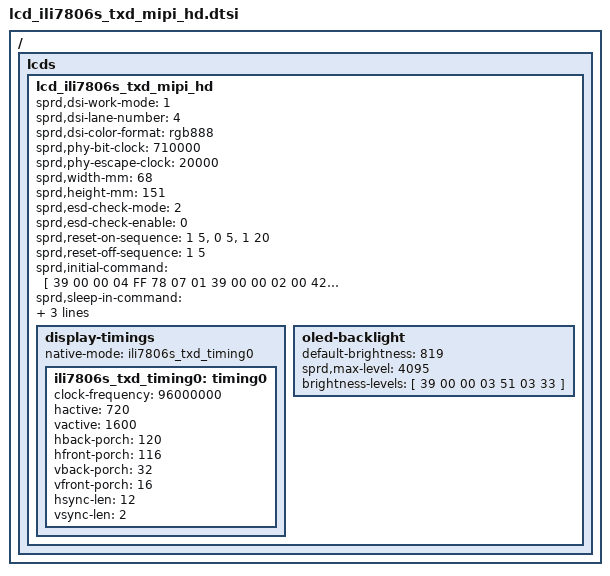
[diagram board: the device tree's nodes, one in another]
/ {
	fragment {
		target-path = "/";
		__overlay__ {
			lcds {
				lcd_ili7806s_txd_mipi_hd: lcd_ili7806s_txd_mipi_hd {
				       sprd,dsi-work-mode = <1>; /* video burst mode*/
				       sprd,dsi-lane-number = <4>;
				       sprd,dsi-color-format = "rgb888";

				       sprd,phy-bit-clock = <710000>;  /* kbps */
				       sprd,phy-escape-clock = <20000>;/* kHz */

				       sprd,width-mm = <68>;
				       sprd,height-mm = <151>;

				       sprd,esd-check-mode = <2>;
				       sprd,esd-check-enable = <0>;

				       sprd,reset-on-sequence = <1 5>, <0 5>, <1 20>;
				       sprd,reset-off-sequence = <1 5>;

				       sprd,initial-command = [
						       39 00 00 04 FF 78 07 01
						       39 00 00 02 00 42
						       39 00 00 02 01 51
						       39 00 00 02 02 00
						       39 00 00 02 03 9F
						       39 00 00 02 04 00
						       39 00 00 02 05 00
						       39 00 00 02 06 00
						       39 00 00 02 07 00
						       39 00 00 02 08 89
						       39 00 00 02 09 0A
						       39 00 00 02 0a 30
						       39 00 00 02 0B 00
						       39 00 00 02 0C 04
						       39 00 00 02 0E 04
						       39 00 00 04 FF 78 07 11
						       39 00 00 02 00 04
						       39 00 00 02 01 04
						       39 00 00 02 18 5A
						       39 00 00 02 19 00
						       39 00 00 02 1A 5A
						       39 00 00 02 1B 6A
						       39 00 00 02 1C 64
						       39 00 00 02 1D 00
						       39 00 00 04 FF 78 07 0E
						       39 00 00 02 02 0D
						       39 00 00 04 FF 78 07 01
						       39 00 00 02 31 07
						       39 00 00 02 32 07
						       39 00 00 02 33 07
						       39 00 00 02 34 07
						       39 00 00 02 35 07
						       39 00 00 02 36 07
						       39 00 00 02 37 07
						       39 00 00 02 38 40
						       39 00 00 02 39 40
						       39 00 00 02 3a 02
						       39 00 00 02 3b 24
						       39 00 00 02 3c 00
						       39 00 00 02 3d 00
						       39 00 00 02 3e 30
						       39 00 00 02 3f 2F
						       39 00 00 02 40 2E
						       39 00 00 02 41 10
						       39 00 00 02 42 12
						       39 00 00 02 43 2D
						       39 00 00 02 44 41
						       39 00 00 02 45 41
						       39 00 00 02 46 01
						       39 00 00 02 47 24
						       39 00 00 02 48 08
						       39 00 00 02 49 07
						       39 00 00 02 4a 07
						       39 00 00 02 4b 07
						       39 00 00 02 4c 07
						       39 00 00 02 4d 07
						       39 00 00 02 4e 07
						       39 00 00 02 4f 07
						       39 00 00 02 50 40
						       39 00 00 02 51 40
						       39 00 00 02 52 02
						       39 00 00 02 53 24
						       39 00 00 02 54 00
						       39 00 00 02 55 00
						       39 00 00 02 56 30
						       39 00 00 02 57 2F
						       39 00 00 02 58 2E
						       39 00 00 02 59 11
						       39 00 00 02 5a 13
						       39 00 00 02 5b 2D
						       39 00 00 02 5c 41
						       39 00 00 02 5d 41
						       39 00 00 02 5e 01
						       39 00 00 02 5f 24
						       39 00 00 02 60 09
						       39 00 00 02 61 07
						       39 00 00 02 62 07
						       39 00 00 02 63 07
						       39 00 00 02 64 07
						       39 00 00 02 65 07
						       39 00 00 02 66 07
						       39 00 00 02 67 07
						       39 00 00 02 68 40
						       39 00 00 02 69 40
						       39 00 00 02 6a 02
						       39 00 00 02 6b 24
						       39 00 00 02 6c 01
						       39 00 00 02 6d 01
						       39 00 00 02 6e 30
						       39 00 00 02 6f 2F
						       39 00 00 02 70 2E
						       39 00 00 02 71 13
						       39 00 00 02 72 11
						       39 00 00 02 73 2D
						       39 00 00 02 74 41
						       39 00 00 02 75 41
						       39 00 00 02 76 24
						       39 00 00 02 77 00
						       39 00 00 02 78 09
						       39 00 00 02 79 07
						       39 00 00 02 7a 07
						       39 00 00 02 7b 07
						       39 00 00 02 7c 07
						       39 00 00 02 7d 07
						       39 00 00 02 7e 07
						       39 00 00 02 7f 07
						       39 00 00 02 80 40
						       39 00 00 02 81 40
						       39 00 00 02 82 02
						       39 00 00 02 83 24
						       39 00 00 02 84 01
						       39 00 00 02 85 01
						       39 00 00 02 86 30
						       39 00 00 02 87 2F
						       39 00 00 02 88 2E
						       39 00 00 02 89 12
						       39 00 00 02 8a 10
						       39 00 00 02 8b 2D
						       39 00 00 02 8c 41
						       39 00 00 02 8d 41
						       39 00 00 02 8e 24
						       39 00 00 02 8f 00
						       39 00 00 02 90 08
						       39 00 00 02 92 10
						       39 00 00 02 A2 4C
						       39 00 00 02 A3 49
						       39 00 00 02 A7 10
						       39 00 00 02 AE 00
						       39 00 00 02 B0 20
						       39 00 00 02 B4 05
						       39 00 00 02 C0 0C
						       39 00 00 02 C6 64
						       39 00 00 02 C7 00
						       39 00 00 02 D1 00
						       39 00 00 02 D2 10
						       39 00 00 02 D4 14
						       39 00 00 02 D5 01
						       39 00 00 02 D7 80
						       39 00 00 02 D8 40
						       39 00 00 02 D9 04
						       39 00 00 02 DF 4A
						       39 00 00 02 DE 03
						       39 00 00 02 DD 08
						       39 00 00 02 E0 00
						       39 00 00 02 E1 28
						       39 00 00 02 E2 06
						       39 00 00 02 E3 31
						       39 00 00 02 E4 02
						       39 00 00 02 E5 6D
						       39 00 00 02 E6 12
						       39 00 00 02 E7 0C
						       39 00 00 02 ED 56
						       39 00 00 02 F4 54
						       39 00 00 04 FF 78 07 02
						       39 00 00 02 01 D5
						       39 00 00 02 47 00
						       39 00 00 02 4F 01
						       39 00 00 02 6B 11
						       39 00 00 04 FF 78 07 12
						       39 00 00 02 10 10
						       39 00 00 02 12 08
						       39 00 00 02 13 4F
						       39 00 00 02 16 08
						       39 00 00 02 3A 05
						       39 00 00 02 C0 A1
						       39 00 00 02 C2 12
						       39 00 00 02 C3 20
						       39 00 00 04 FF 78 07 04
						       39 00 00 02 BD 01
						       39 00 00 04 FF 78 07 04
						       39 00 00 02 B7 CF
						       39 00 00 02 B8 45
						       39 00 00 02 BA 74
						       39 00 00 04 FF 78 07 05
						       39 00 00 02 61 CB
						       39 00 00 04 FF 78 07 07
						       39 00 00 02 07 4C
						       39 00 00 02 11 16
						       39 00 00 02 29 00
						       39 00 00 04 FF 78 07 05
						       39 00 00 02 1C 85
						       39 00 00 02 72 56
						       39 00 00 02 74 56
						       39 00 00 02 76 51
						       39 00 00 02 7A 51
						       39 00 00 02 7B 88
						       39 00 00 02 7C 77
						       39 00 00 02 AE 29
						       39 00 00 02 B1 39
						       39 00 00 02 46 58
						       39 00 00 02 47 78
						       39 00 00 02 B5 58
						       39 00 00 02 B7 78
						       39 00 00 02 3E 50
						       39 00 00 02 C9 90
						       39 00 00 02 56 FF
						       39 00 00 04 FF 78 07 06
						       39 00 00 02 C0 40
						       39 00 00 02 C1 16
						       39 00 00 02 C2 FA
						       39 00 00 02 C3 06
						       39 00 00 02 96 50
						       39 00 00 02 13 13
						       39 00 00 02 B4 DC
						       39 00 00 02 B5 23
						       39 00 00 04 FF 78 07 08
						       39 00 00 20 E0 00 00 57 76 00 A3 C8 E6 15 18 3E 7A 25 A9 F3 2B 2A 64 A4 CD 3F 01 26 51 3F 6D 8E BF 0F D3 D8
						       39 00 00 20 E1 00 88 57 76 00 A3 C8 E6 15 18 3E 7A 25 A9 F3 2B 2A 64 A4 CD 3F 01 26 51 3F 6D 8E BF 0F D3 D8
						       39 00 00 04 FF 78 07 0B
						       39 00 00 02 C0 88
						       39 00 00 02 C1 1F
						       39 00 00 02 C2 06
						       39 00 00 02 C3 06
						       39 00 00 02 C4 CB
						       39 00 00 02 C5 CB
						       39 00 00 02 D2 45
						       39 00 00 02 D3 0A
						       39 00 00 02 D4 04
						       39 00 00 02 D5 04
						       39 00 00 02 D6 7E
						       39 00 00 02 D7 7E
						       39 00 00 02 AB E0
						       39 00 00 04 FF 78 07 0C
						       39 00 00 02 00 27
						       39 00 00 02 01 9D
						       39 00 00 02 02 27
						       39 00 00 02 03 9E
						       39 00 00 02 04 27
						       39 00 00 02 05 9E
						       39 00 00 02 06 27
						       39 00 00 02 07 A5
						       39 00 00 02 08 27
						       39 00 00 02 09 A3
						       39 00 00 02 0A 27
						       39 00 00 02 0B A0
						       39 00 00 02 0C 27
						       39 00 00 02 0D A1
						       39 00 00 02 0E 27
						       39 00 00 02 0F A4
						       39 00 00 02 10 27
						       39 00 00 02 11 A7
						       39 00 00 02 12 27
						       39 00 00 02 13 A6
						       39 00 00 02 14 27
						       39 00 00 02 15 A2
						       39 00 00 04 FF 78 07 0E
						       39 00 00 02 00 A3
						       39 00 00 02 04 00
						       39 00 00 02 20 07
						       39 00 00 02 27 00
						       39 00 00 02 29 C8
						       39 00 00 02 25 0B
						       39 00 00 02 26 0C
						       39 00 00 02 2D 21
						       39 00 00 02 30 04
						       39 00 00 02 21 24
						       39 00 00 02 23 44
						       39 00 00 02 B0 01
						       39 00 00 02 C0 12
						       39 00 00 02 05 20
						       39 00 00 02 2B 0A
						       39 00 00 04 FF 78 07 1E
						       39 00 00 02 A2 00
						       39 00 00 02 AD 02
						       39 00 00 02 00 91
						       39 00 00 02 08 91
						       39 00 00 02 09 91
						       39 00 00 02 0A 10
						       39 00 00 02 0C 08
						       39 00 00 02 0D 4F
						       39 00 00 04 FF 78 07 06
						       39 00 00 02 08 20
						       39 00 00 04 FF 78 07 03
						       39 00 00 02 83 20
						       39 00 00 02 84 00
						       39 00 00 04 FF 78 07 00
						       39 00 00 03 51 00 00
						       39 00 00 02 53 2C
						       39 78 00 02 11 00
						       39 00 00 02 35 00
						       39 14 00 02 29 00
						       ];

				        sprd,sleep-in-command = [
						13 0A 00 02 28 00
						13 78 00 02 10 00
						];
					sprd,sleep-out-command = [
						13 78 00 02 11 00
						13 14 00 02 29 00
						];

					display-timings {
						native-mode = <&ili7806s_txd_timing0>;
						ili7806s_txd_timing0: timing0 {
						clock-frequency = <96000000>;
						hactive = <720>;
						vactive = <1600>;
						hback-porch = <120>;
						hfront-porch = <116>;
						vback-porch = <32>;
						vfront-porch = <16>;
						hsync-len = <12>;
						vsync-len = <2>;
						};
					};

					oled-backlight {
						default-brightness = <819>;
						sprd,max-level = <4095>;
						brightness-levels = [
							39 00 00 03 51 03 33
						];
					};
				};
			};
		};
	};
};
